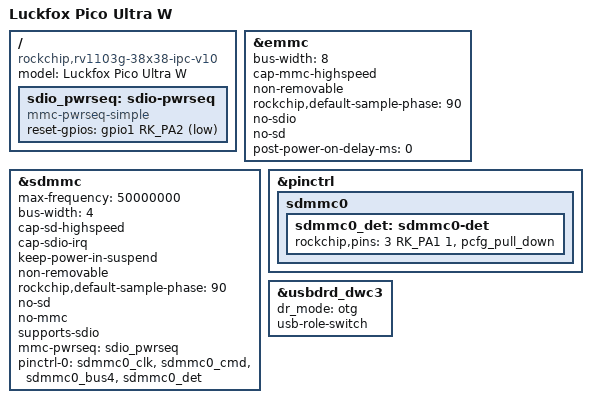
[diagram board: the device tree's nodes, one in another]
// SPDX-License-Identifier: (GPL-2.0+ OR MIT)
/*
 * Copyright (c) 2022 Rockchip Electronics Co., Ltd.
 */

/dts-v1/;
#include "rv1106.dtsi"
#include "rv1106-luckfox-pico-ultra-ipc.dtsi"
#include <dt-bindings/input/input.h>

/ {
	model = "Luckfox Pico Ultra W";
	compatible = "rockchip,rv1103g-38x38-ipc-v10", "rockchip,rv1106g3";

	sdio_pwrseq: sdio-pwrseq {
		compatible = "mmc-pwrseq-simple";
		pinctrl-names = "default";
		reset-gpios = <&gpio1 RK_PA2 GPIO_ACTIVE_LOW>;
	};

	// wireless_bluetooth: wireless-bluetooth {
	// 	compatible = "bluetooth-platdata";
	// 	uart_rts_gpios = <&gpio0 RK_PA5 GPIO_ACTIVE_LOW>;
	// 	pinctrl-names = "default", "rts_gpio";
	// 	pinctrl-0 = <&uart1m0_rtsn>;
	// 	pinctrl-1 = <&uart1_gpios>;
	// 	BT,wake_gpio     = <&gpio0 RK_PA2 GPIO_ACTIVE_HIGH>;
	// 	BT,wake_host_irq = <&gpio1 RK_PA2 GPIO_ACTIVE_HIGH>;
	// 	status = "okay";
	// };
};

/**********CRU**********/
//&cru {
//	assigned-clocks =
//		<&cru PLL_GPLL>, <&cru PLL_CPLL>,
//		<&cru ARMCLK>,
//		<&cru ACLK_PERI_ROOT>, <&cru HCLK_PERI_ROOT>,
//		<&cru PCLK_PERI_ROOT>, <&cru ACLK_BUS_ROOT>,
//		<&cru PCLK_TOP_ROOT>, <&cru PCLK_PMU_ROOT>,
//		<&cru HCLK_PMU_ROOT>, <&cru CLK_500M_SRC>;
//	assigned-clock-rates =
//		<1188000000>, <700000000>,
//		<1104000000>,
//		<400000000>, <200000000>,
//		<100000000>, <300000000>,
//		<100000000>, <100000000>,
//		<200000000>, <700000000>;
//};

/**********EMMC**********/
&emmc {
	bus-width = <8>;
	cap-mmc-highspeed;
	non-removable;
	rockchip,default-sample-phase = <90>;
	no-sdio;
	no-sd;
	post-power-on-delay-ms = <0>;
	status = "okay";
};

/**********SDIO-WIFI**********/
&sdmmc {
	max-frequency = <50000000>;
	bus-width = <4>;
	cap-sd-highspeed;
	cap-sdio-irq;
	keep-power-in-suspend;
	non-removable;
	rockchip,default-sample-phase = <90>;
	no-sd;
	no-mmc;
	supports-sdio;
	mmc-pwrseq = <&sdio_pwrseq>;
	pinctrl-names = "default";
	pinctrl-0 = <&sdmmc0_clk &sdmmc0_cmd &sdmmc0_bus4 &sdmmc0_det>;
	status = "okay";
};

&pinctrl {
	sdmmc0 {
		/omit-if-no-ref/
		sdmmc0_det: sdmmc0-det {
			rockchip,pins =
				/* sdmmc0_det */
				<3 RK_PA1 1 &pcfg_pull_down>;
		};
	};
};

&usbdrd_dwc3 {
	status = "okay";
	dr_mode = "otg";
	usb-role-switch;
};
